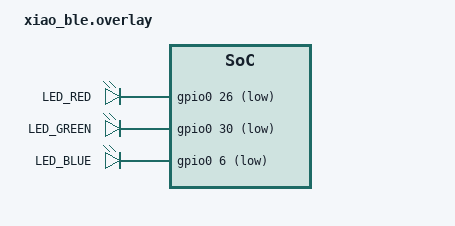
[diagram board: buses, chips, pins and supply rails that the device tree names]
/ {
    leds {
        compatible = "gpio-leds";

        led_red: led_red {
            gpios = <&gpio0 26 GPIO_ACTIVE_LOW>;
            label = "LED_RED";
        };

        led_green: led_green {
            gpios = <&gpio0 30 GPIO_ACTIVE_LOW>;
            label = "LED_GREEN";
        };

        led_blue: led_blue {
            gpios = <&gpio0 6 GPIO_ACTIVE_LOW>;
            label = "LED_BLUE";
        };
    };
    behaviors {
        blue_on: blue_on {
            compatible = "zmk,behavior-gpio-toggle";
            #binding-cells = <0>;
            gpios = <&gpio0 6 GPIO_ACTIVE_LOW>;
        };
    };
};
